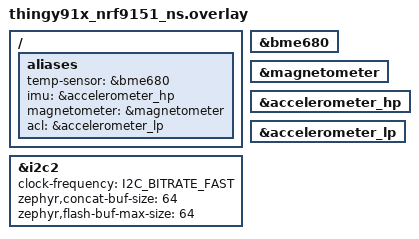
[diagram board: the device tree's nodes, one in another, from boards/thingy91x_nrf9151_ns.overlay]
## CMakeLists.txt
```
cmake_minimum_required(VERSION 3.20.0)


find_package(Zephyr REQUIRED HINTS $ENV{ZEPHYR_BASE})
project(yes)

# NORDIC SDK APP START
target_sources(app PRIVATE src/encryption_helper.c)
target_sources(app PRIVATE src/mqtt_connection.c)
target_sources(app PRIVATE src/heartbeat.c)
target_sources(app PRIVATE src/shell_commands.c)
target_sources(app PRIVATE src/config.c)
target_sources(app PRIVATE src/main.c)
target_sources(app PRIVATE src/gnss.c)
target_sources(app PRIVATE src/lte_helper.c)
target_sources(app PRIVATE src/fota.c)
target_sources(app PRIVATE drivers/led/led_driver.c)
target_sources(app PRIVATE src/pem_command.c)
target_sources(app PRIVATE src/sensor.c)
target_sources(app PRIVATE src/modem_info.c)
# NORDIC SDK APP END
```

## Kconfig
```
#  Kestrel Device Configuration

menu "Tracker Demo"
config TRACKER_VERSION_MAJOR
	int "Major verison number"
	default 0

config TRACKER_VERSION_MINOR
	int "Minor verison number"
	default 2

config TRACKER_VERSION_PATCH
	int "Patch verison number"
	default 0

config MQTT_CLIENT_ID
	string "Device ID"
	help
	  Use a custom Device ID string. If not set, the ID will be
	  generated based on IMEI number (for nRF91 Series based targets) or
	  randomly (for other platforms).
	default "359404230244148"

config MQTT_SUB_TOPIC
	string "MQTT subscribe topic"
	default "/input"

config MQTT_BROKER_HOSTNAME
	string "MQTT broker hostname"
	default "18.234.99.151"

config MQTT_BROKER_PORT
	int "MQTT broker port"
	default 8883

config MQTT_MESSAGE_BUFFER_SIZE
	int "MQTT message buffer size"
	default 128

config MQTT_PAYLOAD_BUFFER_SIZE
	int "MQTT payload buffer size"
	default 256

config MQTT_PUBLISH_INTERVAL
	int "Fix interval (sec) for publishing the GPS fixes"
	range 1 600
	default 1
	help
	  Fix interval (in seconds) for publishing GPS fixes.
      
config MQTT_RECONNECT_DELAY_S
	int "Seconds to delay before attempting to reconnect to the broker."
	default 60

config BUTTON_EVENT_PUBLISH_MSG
	string "The message to publish on a button event"
	default "Test Message"

config TLS
	bool "Enable TLS"
	default y
endmenu

menu "Zephyr Kernel"
source "Kconfig.zephyr"
endmenu
```

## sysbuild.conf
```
SB_CONFIG_BOOTLOADER_MCUBOOT=y


SB_CONFIG_BOOT_SIGNATURE_KEY_FILE="C:/Nordic/myApps/key_file/mcu_sign.pem"
SB_CONFIG_BOOT_SIGNATURE_TYPE_ECDSA_P256=y
#SB_CONFIG_SECURE_BOOT_SIGNING_KEY_FILE="C:/Nordic/myApps/key_file/mcu_sign.pem"
#SB_CONFIG_SECURE_BOOT_SIGNATURE_TYPE_ECDSA=y
```

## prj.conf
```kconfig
# System
CONFIG_REBOOT=y

# Logging
CONFIG_LOG=y
CONFIG_LOG_PRINTK=y
CONFIG_LOG_CMDS=y
CONFIG_LOG_DEFAULT_LEVEL=3
# Enable log colors
CONFIG_LOG_BACKEND_SHOW_COLOR=y


CONFIG_SERIAL=y
CONFIG_GPIO=y
CONFIG_I2C_GPIO=y

# Peripherals
CONFIG_DK_LIBRARY=y
CONFIG_I2C=y


# Newlib
CONFIG_NEWLIB_LIBC=y
CONFIG_FPU=y
CONFIG_NEWLIB_LIBC_FLOAT_PRINTF=y

# Networking
CONFIG_NETWORKING=y
CONFIG_NET_NATIVE=n
CONFIG_NET_SOCKETS_OFFLOAD=y
CONFIG_NET_SOCKETS=y
CONFIG_POSIX_API=y

# Memory
CONFIG_THREAD_ANALYZER=y


# Modem library
CONFIG_NRF_MODEM_LIB=y
CONFIG_MODEM_KEY_MGMT=y
CONFIG_MODEM_INFO=y
CONFIG_MODEM_INFO_ADD_NETWORK=y
CONFIG_MODEM_INFO_ADD_SIM=y
CONFIG_MODEM_INFO_ADD_SIM_IMSI=y
CONFIG_MODEM_INFO_ADD_SIM_ICCID=y
CONFIG_MODEM_INFO_ADD_DEVICE=y
CONFIG_MODEM_INFO_ADD_DATE_TIME=n


# LTE link control
CONFIG_LTE_LINK_CONTROL=y
CONFIG_LTE_NETWORK_MODE_LTE_M_NBIOT_GPS=y
CONFIG_LTE_LC_EDRX_MODULE=n
CONFIG_LTE_LC_PSM_MODULE=y

# AT commands interface
CONFIG_AT_HOST_LIBRARY=n
CONFIG_UART_INTERRUPT_DRIVEN=y

# MQTT
# Enable and configure the MQTT library
CONFIG_MQTT_LIB=y
CONFIG_MQTT_CLEAN_SESSION=y

# Core settings API
CONFIG_SETTINGS=y

# Store in a flash circular buffer
CONFIG_FCB=y
CONFIG_SETTINGS_FCB=y
CONFIG_SETTINGS=y

# Flash and mapping
CONFIG_FLASH=y
CONFIG_FLASH_MAP=y

# Shell & logging on your existing console

CONFIG_DK_LIBRARY=y
CONFIG_GPIO=y
CONFIG_SENSOR=y
CONFIG_NRF_MODEM_LIB=y

CONFIG_NET_PKT_RX_COUNT=4
CONFIG_NET_BUF_RX_COUNT=8
CONFIG_NET_BUF_DATA_SIZE=256

CONFIG_MAIN_STACK_SIZE=10000
#CONFIG_LOG_BUFFER_SIZE=6000
CONFIG_HEAP_MEM_POOL_SIZE=40000  
CONFIG_SHELL_STACK_SIZE=6096
CONFIG_SYSTEM_WORKQUEUE_STACK_SIZE=8096
CONFIG_MBEDTLS_HEAP_SIZE=1500

#TLS
CONFIG_NETWORKING=y
CONFIG_NET_NATIVE=n
CONFIG_NET_SOCKETS_OFFLOAD=y
# Enable TLS support in Zephyr sockets
CONFIG_NET_SOCKETS=y
CONFIG_MQTT_LIB_TLS=y
# Enable MbedTLS for TLS
CONFIG_MBEDTLS=y
CONFIG_MBEDTLS_ENABLE_HEAP=y
# Enable modem TLS credential storage
CONFIG_MODEM_KEY_MGMT=y

#crypto
# Enable PSA Crypto core
CONFIG_NRF_SECURITY=y
CONFIG_BUILD_WITH_TFM=y
CONFIG_MBEDTLS_PSA_CRYPTO_C=y
CONFIG_PSA_WANT_GENERATE_RANDOM=y
CONFIG_PSA_WANT_KEY_TYPE_AES=y
CONFIG_PSA_WANT_ALG_GCM=y
CONFIG_TFM_PROFILE_TYPE_NOT_SET=y
CONFIG_PSA_CRYPTO_DRIVER_CC3XX=y
CONFIG_PM_PARTITION_SIZE_TFM_SRAM=0x10000
CONFIG_BOOTLOADER_MCUBOOT=y
CONFIG_MBEDTLS_PSA_CRYPTO_STORAGE_C=y
CONFIG_TFM_ITS_ENCRYPTED=y
CONFIG_PSA_WANT_ALG_PBKDF2_HMAC=y
CONFIG_PSA_WANT_ALG_SHA3_256=y
CONFIG_PSA_WANT_KEY_TYPE_PASSWORD=y
CONFIG_PSA_WANT_ALG_HMAC=y

# Image manager
CONFIG_IMG_MANAGER=y
CONFIG_FLASH=y
CONFIG_FLASH_MAP=y
CONFIG_STREAM_FLASH=y
CONFIG_IMG_ERASE_PROGRESSIVELY=y
CONFIG_DOWNLOADER=y
CONFIG_DOWNLOADER_STACK_SIZE=4096
CONFIG_DFU_TARGET=y
CONFIG_MODEM_KEY_MGMT=y
CONFIG_FOTA_DOWNLOAD=y

CONFIG_SHELL_STACK_SIZE=6096
CONFIG_SHELL=y
CONFIG_SHELL_CMDS=y
CONFIG_SHELL_DEVICE_HELPERS=n
CONFIG_SHELL=y
CONFIG_SHELL_BACKEND_SERIAL=y   # use the existing console UART/USB-CDC
CONFIG_SHELL_LOG_BACKEND=y      # pipe LOG_* into the shell prompt
CONFIG_UART_INTERRUPT_DRIVEN=y  # required by the shell’s serial backend
CONFIG_SHELL_PROMPT_UART="x"
CONFIG_NEWLIB_LIBC=y
CONFIG_DATE_SHELL=n
CONFIG_DEVICE_SHELL=y
CONFIG_DEVMEM_SHELL=y
CONFIG_KERNEL_SHELL=y
CONFIG_I2C_SHELL=y
CONFIG_SHELL_BACKEND_SERIAL_RX_RING_BUFFER_SIZE=528
CONFIG_SPI=y
CONFIG_SPI_SHELL=y
CONFIG_SENSOR_SHELL=y
CONFIG_AT_SHELL=y

CONFIG_NET_BUF=y
CONFIG_ZCBOR=y
CONFIG_CRC=y
CONFIG_MCUMGR=y
CONFIG_STREAM_FLASH=y
CONFIG_FLASH_MAP=y
CONFIG_THREAD_MONITOR=y
CONFIG_MCUMGR_GRP_OS_TASKSTAT=y
CONFIG_STATS=y
CONFIG_STATS_NAMES=y
CONFIG_FLASH=y
CONFIG_IMG_MANAGER=y
CONFIG_MCUMGR_GRP_IMG=y
CONFIG_MCUMGR_GRP_OS=y
CONFIG_MCUMGR_GRP_STAT=y
CONFIG_MCUBOOT_UTIL_LOG_LEVEL_WRN=y
CONFIG_MCUMGR_GRP_OS_ECHO=y
CONFIG_BASE64=y
CONFIG_CRC=y
CONFIG_MCUMGR_TRANSPORT_UART=y
CONFIG_CONSOLE=y
CONFIG_UART_INTERRUPT_DRIVEN=y
# CONFIG_UART_CONSOLE=n
# CONFIG_SHELL=y
# CONFIG_SHELL_BACKEND_DUMMY=y
# CONFIG_MCUMGR_TRANSPORT_DUMMY=y
# CONFIG_MCUMGR_TRANSPORT_SHELL=y
# CONFIG_SHELL_LOG_BACKEND=n
# CONFIG_SHELL_BACKEND_SERIAL=n

# CONFIG_MCUMGR_LOG_LEVEL_DBG=y
# CONFIG_DOWNLOADER_LOG_LEVEL_DBG=y
# CONFIG_FOTA_DOWNLOAD_LOG_LEVEL_DBG=y
# CONFIG_LTE_LINK_CONTROL_LOG_LEVEL_DBG=y


CONFIG_SENSOR=y
CONFIG_BMP388=y
CONFIG_IIS2MDC=y
CONFIG_ICM42688=y
CONFIG_WATCHDOG=y
```

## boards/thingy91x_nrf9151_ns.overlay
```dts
&i2c2 {
	status = "okay";
	clock-frequency = <I2C_BITRATE_FAST>;
    zephyr,concat-buf-size = <64>;
    zephyr,flash-buf-max-size = <64>;
};

&bme680 {
	status = "okay";
};

&magnetometer {
    status = "okay";
};

&accelerometer_hp {
    status = "okay";
};

&accelerometer_lp {
    status = "okay";
};

/ {

	aliases {
		temp-sensor = &bme680;
		imu = &accelerometer_hp;
		magnetometer = &magnetometer;
		acl = &accelerometer_lp;
	};
};
```

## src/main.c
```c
#include <stdio.h>
#include <string.h>
#include <stdlib.h>
#include <zephyr/device.h>
#include <zephyr/drivers/gpio.h>
#include <zephyr/devicetree.h>
#include <zephyr/kernel.h>
#include <zephyr/sys/reboot.h>
#include <zephyr/net/socket.h>
#include <zephyr/net/mqtt.h>
#include <modem/nrf_modem_lib.h>
#include <modem/lte_lc.h>
#include <modem/modem_info.h>
#include <dk_buttons_and_leds.h>
#include <nrf_modem_gnss.h>
#include <nrf_modem_at.h>
#include <zephyr/sys/heap_listener.h>
#include "mqtt_connection.h"
#include "gnss.h"
#include "nrf.h"
#include "heartbeat.h"
#include "lte_helper.h"
#include "shell_commands.h"
#include "modem_info.h"
#include "fota.h"
#include "config.h"
#include "encryption_helper.h"
#include "sensor.h"
#include "../drivers/led/led_driver.h"
#include <zephyr/drivers/watchdog.h>
LOG_MODULE_REGISTER(loop, LOG_LEVEL_INF);

//Watchdog timer setup for main
#define WDT_TIMEOUT_MS 120000
static const struct device *wdt;
static int wdt_chan_id;


/* Initialize the watchdog */
int wdt_init(void)
{
    wdt = DEVICE_DT_GET(DT_NODELABEL(wdt0));
    if (!device_is_ready(wdt)) {
        LOG_ERR("WDT device not ready");
        return -ENODEV;
    }

    struct wdt_timeout_cfg wdt_cfg = {
    .window.min = 0,
    .window.max = 16384,    
    .flags = WDT_FLAG_RESET_SOC
    };

    wdt_chan_id = wdt_install_timeout(wdt, &wdt_cfg);
    if (wdt_chan_id < 0) {
        LOG_ERR("Failed to install WDT timeout, err: %d", wdt_chan_id);
        return wdt_chan_id;
    }

    int err = wdt_setup(wdt, WDT_OPT_PAUSE_HALTED_BY_DBG);
    if (err < 0) {
        LOG_ERR("Failed to setup WDT, err: %d", err);
        return err;
    }

    LOG_INF("Watchdog initialized with %d ms timeout", WDT_TIMEOUT_MS);
    return 0;
}




/**
 * @brief Initialize all system components
 */
static int init(void)
{
    int err = 0;
    
    LOG_INF("NEW APP STARTING");
    
    

    err = open_persistent_key();
    if (err) {
        LOG_ERR("open_persistent_key: %d", err);
    } else {
        LOG_INF("Persistent key opened successfully");
    }

    const struct device *i2c = DEVICE_DT_GET(DT_NODELABEL(i2c_bb0));
    if (device_is_ready(i2c) && ktd2026_init(&g_ktd, i2c, 0x30) == 0 && ktd2026_init(&k_ktd, i2c, 0x31) == 0) {
        LOG_INF("KTD2026 initialized successfully");
        ktd2026_blink_white_1hz_30();
        ktd2026_blink_white_1hz_31();
    } 
    else {
        LOG_ERR("Failed to initialize KTD2026 LED driver");
        return -ENODEV;
    }


    sensor_init();
    k_sleep(K_MSEC(30000)); // Wait for sensor initialization
    parse_encrypted_blob(); 
    config_init();
    gnss_int();
    err = modem_configure();
    if (err) {
        LOG_ERR("modem_configure failed: %d", err);
        return err;
    }
    lte_data_start();
    mqtt_init();

    return 0;
}

/**
 * @brief Main application entry point
 */
int main(void)
{
    int err, start, end;
    k_sleep(K_MSEC(2000));
    if (boot_write_img_confirmed() != 0) {
        printk("Failed to confirm firmware!\n");
    } else {
        printk("Firmware confirmed!\n");
    }


    

    err = init();
    if (err) {
        LOG_ERR("Initialization failed: %d", err);
    } else {
        LOG_INF("INIT GOOD");
    }
    
    if (wdt_init() != 0) {
        LOG_ERR("Watchdog initialization failed!");
    }

    while (1) {
        start = k_uptime_get();
        gnss_main_loop();
        wdt_feed(wdt, wdt_chan_id);
        end = k_uptime_get();
    }
    
    return 0;
}
```

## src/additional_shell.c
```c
/* Revised KTD2026EWE-TR Zephyr Shell Driver */
#include <zephyr/kernel.h>
#include <zephyr/shell/shell.h>
#include <zephyr/drivers/i2c.h>
#include <zephyr/device.h>
#include <zephyr/logging/log.h>
#include <stdlib.h>
#include <errno.h>
#include <string.h>

LOG_MODULE_REGISTER(led_shell, LOG_LEVEL_INF);

#define KTD2026_I2C_ADDR 0x30
static const struct device *i2c_dev = DEVICE_DT_GET(DT_NODELABEL(i2c1));

#define KTD2026_EN_RST          0x00
#define KTD2026_FLASH_PERIOD    0x01
#define KTD2026_FLASH_DUTY      0x02
#define KTD2026_LED_EN          0x03
#define KTD2026_TRISE_TFALL     0x04
#define KTD2026_LED1            0x05
#define KTD2026_LED2            0x06
#define KTD2026_LED3            0x07
#define KTD2026_TIMER_CTRL      0x08

#define KTD2026_LED_CURRENT_MAX 0xBF
#define KTD2026_FLASH_PERIOD_MAX 0x1F
#define KTD2026_FLASH_DUTY_MAX   0x07

static uint8_t led_en_state = 0;

static int ktd2026_write_reg(uint8_t reg, uint8_t value)
{
    uint8_t buf[2] = {reg, value};
    for (int i = 0; i < 3; i++) {
        int ret = i2c_write(i2c_dev, buf, sizeof(buf), KTD2026_I2C_ADDR);
        if (ret == 0) {
            LOG_DBG("Wrote reg 0x%02X = 0x%02X, ret=%d", reg, value, ret);
            return 0;
        }
        k_sleep(K_MSEC(5));
    }

    LOG_DBG("Wrote reg 0x%02X = 0x%02X, ret=%d", reg, value, ret);
    return -EIO;
}

static int ktd2026_read_reg(uint8_t reg, uint8_t *value)
{
    return i2c_write_read(i2c_dev, KTD2026_I2C_ADDR, &reg, 1, value, 1);
}

static int ktd2026_set_led_current(uint8_t led, uint8_t current)
{
    if (current > KTD2026_LED_CURRENT_MAX) current = KTD2026_LED_CURRENT_MAX;
    uint8_t reg = (led == 1) ? KTD2026_LED1 : (led == 2) ? KTD2026_LED2 : (led == 3) ? KTD2026_LED3 : 0xFF;
    if (reg == 0xFF) return -EINVAL;
    return ktd2026_write_reg(reg, current);
}

static int ktd2026_set_led_enable(uint8_t led, bool enable)
{
    if (led < 1 || led > 3) return -EINVAL;
    uint8_t bit = BIT(led - 1);
    led_en_state = enable ? (led_en_state | bit) : (led_en_state & ~bit);
    return ktd2026_write_reg(KTD2026_LED_EN, led_en_state);
}

static int ktd2026_set_flash_period(uint8_t period)
{
    if (period > KTD2026_FLASH_PERIOD_MAX) period = KTD2026_FLASH_PERIOD_MAX;
    return ktd2026_write_reg(KTD2026_FLASH_PERIOD, period);
}

static int ktd2026_set_flash_duty(uint8_t duty)
{
    if (duty > KTD2026_FLASH_DUTY_MAX) duty = KTD2026_FLASH_DUTY_MAX;
    return ktd2026_write_reg(KTD2026_FLASH_DUTY, duty);
}

static int ktd2026_set_timer_control(uint8_t timer_sel, bool enable)
{
    uint8_t value;
    if (ktd2026_read_reg(KTD2026_TIMER_CTRL, &value) < 0) return -EIO;
    value &= ~0x06;
    value |= (timer_sel << 1) & 0x06;
    value = enable ? (value | 0x01) : (value & ~0x01);
    return ktd2026_write_reg(KTD2026_TIMER_CTRL, value);
}

static int ktd2026_init(void)
{
    if (!device_is_ready(i2c_dev)) {
        LOG_ERR("I2C device not ready");
        return -ENODEV;
    }
    k_sleep(K_MSEC(1));
    if (ktd2026_write_reg(KTD2026_EN_RST, 0x00) < 0) return -EIO;
    k_sleep(K_MSEC(10));
    if (ktd2026_write_reg(KTD2026_LED_EN, 0x00) < 0) return -EIO;
    for (int i = 1; i <= 3; i++) {
        if (ktd2026_set_led_current(i, 0) < 0) return -EIO;
    }
    if (ktd2026_write_reg(KTD2026_TIMER_CTRL, 0x00) < 0) return -EIO;
    return 0;
}

/* Shell Commands */
static int cmd_led_init(const struct shell *shell, size_t argc, char *argv[]) {
    int ret = ktd2026_init();
    shell_print(shell, ret == 0 ? "LED controller initialized" : "Init failed: %d", ret);
    return ret;
}

static int cmd_led_on(const struct shell *shell, size_t argc, char *argv[]) {
    if (argc != 2) return -EINVAL;
    int led = atoi(argv[1]);
    return ktd2026_set_led_enable(led, true);
}

static int cmd_led_off(const struct shell *shell, size_t argc, char *argv[]) {
    if (argc != 2) return -EINVAL;
    int led = atoi(argv[1]);
    return ktd2026_set_led_enable(led, false);
}

static int cmd_led_set(const struct shell *shell, size_t argc, char *argv[]) {
    if (argc != 3) return -EINVAL;
    int led = atoi(argv[1]);
    int current = atoi(argv[2]);
    return ktd2026_set_led_current(led, current);
}

SHELL_STATIC_SUBCMD_SET_CREATE(led_subcmds,
    SHELL_CMD(init, NULL, "Initialize LED controller", cmd_led_init),
    SHELL_CMD(on, NULL, "Turn LED on", cmd_led_on),
    SHELL_CMD(off, NULL, "Turn LED off", cmd_led_off),
    SHELL_CMD(set, NULL, "Set LED current", cmd_led_set),
    SHELL_SUBCMD_SET_END
);

SHELL_CMD_REGISTER(led, &led_subcmds, "KTD2026 LED driver commands", NULL);


static int cmd_dfu_reboot(const struct shell *shell, size_t argc, char **argv)
{
    ARG_UNUSED(argc);
    ARG_UNUSED(argv);

    int err = boot_write_img_confirmed();
    if (err != 0) {
        shell_error(shell, "Failed to confirm image: %d", err);
        return err;
    }

    err = boot_set_pending(false);  // false = permanent
    if (err != 0) {
        shell_error(shell, "Failed to set boot pending: %d", err);
        return err;
    }

    shell_print(shell, "Rebooting into MCUboot for DFU...");
    k_sleep(K_MSEC(100)); // allow shell print to flush

    sys_reboot(SYS_REBOOT_COLD);
    return 0; // won't be reached
}

SHELL_CMD_REGISTER(dfu_reboot, NULL, "Reboot into MCUboot DFU mode", cmd_dfu_reboot);
```

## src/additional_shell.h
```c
#ifndef ADDITIONAL_SHELL_H
#define ADDITIONAL_SHELL_H

#include <zephyr/shell/shell.h>

/* LED shell command declarations */
extern const struct shell *led_shell;

#endif /* ADDITIONAL_SHELL_H */ 
```

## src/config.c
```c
#include "config.h"
#include <stdio.h>
#include <string.h>
#include <stdlib.h>
#include <zephyr/logging/log.h>
#include <zephyr/logging/log.h>
#include <zephyr/kernel.h>
#include <zephyr/sys/reboot.h>
#include <zephyr/net/socket.h>
#include <zephyr/net/mqtt.h>
#include <zephyr/net/tls_credentials.h>
#include <zephyr/random/random.h>
#include <nrf_modem_at.h>
#include <modem/modem_key_mgmt.h>
#include <zephyr/sys/crc.h>
#include <zephyr/storage/flash_map.h>
#include "encryption_helper.h"

LOG_MODULE_REGISTER(configuration, LOG_LEVEL_INF);
char json_payload[JSON_BUF_SIZE] = "NO PVT";
char sensor_payload[JSON_BUF_SIZE] = "NO SENSOR DATA";
char json_payload_lte[JSON_BUF_SIZE] = "NO LTE";
char json_bmp390[JSON_BUF_SIZE] = "NO BMP390 DATA";
char json_iis2mdc[JSON_BUF_SIZE] = "NO IIS2MDC DATA";
char json_icm42688[JSON_BUF_SIZE] = "NO ICM42688 DATA";
char topic_gps[DEFAULT_LEN] = "/gps";
char topic_sensor[DEFAULT_LEN] = "/sensor";
char topic_lte[DEFAULT_LEN] = "/lte";
char pwd[64] = "Kalscott123";
char usr[64] = "admin";
char firmware_filename[FOTA_FILE_NAME_MAX_LEN] = "firmware.bin";
struct mqtt_utf8 struct_pass;
struct mqtt_utf8 struct_user;
system_enable_t sys_enable_config;
enum fota_state current_state = FOTA_IDLE;
mqtt_config_t mqtt_config;
ota_config_t ota_config;
hardware_info_t hw_info;
modem_info_t modem_info;
sensor_config_t sensor_config;
gnss_config_t gnss_config;
customer_info_t customer_info;
message_settings_t msg_settings;


ConfigEntry entries[MAX_ENTRIES];
int num_entries = 0;

void set_filename(void) {
    const char root[] = "firmware_storage";
    const char file[] = "zephyr_signed.bin";

    char customer[MQTT_MAX_STR_LEN];
    char device[MQTT_MAX_STR_LEN];


    // copy results immediately so we don't lose them
    const char *cfg_val = get_config("name");
    if (cfg_val) {
        strncpy(customer, cfg_val, sizeof(customer));
        customer[sizeof(customer) - 1] = '\0'; // ensure null-terminated
    } else {
        customer[0] = '\0';
    }

    cfg_val = get_config("mq_clid");
    if (cfg_val) {
        strncpy(device, cfg_val, sizeof(device));
        device[sizeof(device) - 1] = '\0';
    } else {
        device[0] = '\0';
    }

    // build path
    snprintf(firmware_filename, sizeof(firmware_filename),
             "%s/%s/%s/%s", root, customer, device, file);

    printf("Firmware filename: %s\n", firmware_filename);
}


int update_crc(void)
{
    const struct flash_area *fa;
    int err = flash_area_open(FLASH_AREA_ID(encrypted_blob_slot0), &fa);
    if (err) {
        LOG_ERR("flash_area_open for CRC failed: %d", err);
        return err;
    }

    uint32_t new_crc = manual_crc32(ENCRYPTED_BLOB_ADDR, ENCRYPTED_BLOB_SIZE - 4);
    uint32_t crc_offset = CRC_LOCATION_OFFSET;
    uint32_t page_start = (crc_offset / FLASH_PAGE_SIZE) * FLASH_PAGE_SIZE;

    static uint8_t page_buf[FLASH_PAGE_SIZE];

    err = flash_area_read(fa, page_start, page_buf, FLASH_PAGE_SIZE);
    if (err) {
        LOG_ERR("flash_area_read for CRC page failed: %d", err);
        flash_area_close(fa);
        return err;
    }

    uint32_t crc_offset_in_page = crc_offset - page_start;
    memcpy(&page_buf[crc_offset_in_page], &new_crc, 4);

    err = flash_area_erase(fa, page_start, FLASH_PAGE_SIZE);
    if (err) {
        LOG_ERR("flash_area_erase CRC page failed: %d", err);
        flash_area_close(fa);
        return err;
    }

    err = flash_area_write(fa, page_start, page_buf, FLASH_PAGE_SIZE);
    if (err) {
        LOG_ERR("CRC write failed: %d", err);
    } else {
        LOG_INF("CRC updated: 0x%08X at offset 0x%x", new_crc, crc_offset);
    }

    flash_area_close(fa);
    return err;
}

uint32_t manual_crc32(const uint8_t *data, size_t len) {
    uint32_t crc = 0xFFFFFFFF;

    LOG_INF("Starting manual CRC-32 over %u bytes", (unsigned int)len);

    for (size_t i = 0; i < len; i++) {
        uint8_t byte = data[i];
        crc ^= byte;
        for (int j = 0; j < 8; j++) {
            if (crc & 1)
                crc = (crc >> 1) ^ 0xEDB88320;
            else
                crc >>= 1;
        }
    }

    crc ^= 0xFFFFFFFF;

    LOG_INF("Final manual CRC-32: 0x%08X", crc);
    return crc;
}

const char *get_config(const char *aad)
{
    static char decrypted[DECRYPTED_OUTPUT_MAX]; // persistent output
    size_t decrypted_len = 0;

    for (int i = 0; i < num_entries; i++) {
        ConfigEntry *e = &entries[i];

        if (e->aad_len == strlen(aad) &&
            memcmp(e->aad, aad, e->aad_len) == 0) {

            int ret = decrypt_config_field_data(
                (const char *)e->ciphertext, e->ciphertext_len,
                (const char *)e->iv,
                (const char *)e->aad, e->aad_len,
                decrypted, &decrypted_len
            );

            if (ret != 0) {
                LOG_ERR("Decryption failed for AAD: %s", aad);
                return NULL;
            }

            decrypted[decrypted_len] = '\0'; // null-terminate
            return decrypted;
        }
    }

    LOG_WRN("AAD not found: %s", aad);
    return "NULL";
}

void parse_encrypted_blob(void)
{
    const uint8_t *start = ENCRYPTED_BLOB_ADDR;
    const uint8_t *end = ENCRYPTED_BLOB_ADDR + ENCRYPTED_BLOB_SIZE;
    const size_t entry_span = ENTRY_SIZE;
    const size_t max_offset = CRC_LOCATION_OFFSET;

    LOG_INF("Begin blob parsing at address %p, total size: %d", (void *)start, ENCRYPTED_BLOB_SIZE);

    uint32_t computed_crc = manual_crc32(start, ENCRYPTED_BLOB_SIZE - 4);
    uint32_t stored_crc = *(uint32_t *)(start + CRC_LOCATION_OFFSET);
    if (computed_crc != stored_crc) {
        LOG_WRN("CRC mismatch: computed=0x%08X, stored=0x%08X", computed_crc, stored_crc);
    } else {
        LOG_INF("CRC check passed: 0x%08X", computed_crc);
    }

    num_entries = 0;

    for (uintptr_t offset = 0; offset + entry_span <= max_offset && num_entries < MAX_ENTRIES; offset += entry_span) {
        const uint8_t *ptr = start + offset;

        if (ptr[0] == 0xFF) {
            continue;
        }

        ConfigEntry *e = &entries[num_entries];
        e->mem_offset = offset;

        e->iv_len = *ptr++;
        if (e->iv_len > MAX_IV_LEN || ptr + e->iv_len > end) {
            LOG_ERR("Invalid or oversized IV length: %d at entry %d", e->iv_len, num_entries);
            continue;
        }
        memcpy(e->iv, ptr, e->iv_len);
        ptr += e->iv_len;

        if (ptr + 2 > end) continue;
        e->aad_len = ptr[0] | (ptr[1] << 8);
        ptr += 2;
        if (e->aad_len > MAX_AAD_LEN || ptr + e->aad_len > end) {
            LOG_ERR("Invalid or oversized AAD length: %d at entry %d", e->aad_len, num_entries);
            continue;
        }
        memcpy(e->aad, ptr, e->aad_len);
        ptr += e->aad_len;

        if (ptr + 2 > end) continue;
        e->ciphertext_len = ptr[0] | (ptr[1] << 8);
        ptr += 2;
        if (e->ciphertext_len > MAX_CIPHERTEXT_LEN || ptr + e->ciphertext_len > end) {
            LOG_ERR("Invalid or oversized ciphertext length: %d at entry %d", e->ciphertext_len, num_entries);
            continue;
        }
        memcpy(e->ciphertext, ptr, e->ciphertext_len);
        ptr += e->ciphertext_len;

        LOG_INF("Parsed entry %d @ offset 0x%04X: IV=%d, AAD=%d, Cipher+Tag=%d",
                num_entries, (int)offset, e->iv_len, e->aad_len, e->ciphertext_len);

        num_entries++;
    }

    LOG_INF("Total parsed entries: %d", num_entries);
}

void parse_hardware_info(hardware_info_t *cfg) {
    const char *val;

    if (!cfg) {
    LOG_ERR("parse_hardware_info: cfg is NULL!");
    return;
    }
    cfg->sn[0] = cfg->hw_ver[0] = cfg->fw_ver[0] = '\0';
    cfg->power_enabled = false;


    val = get_config("hw_info");
    if (val) {

        sscanf(val, "%31[^,],%15[^,],%15[^,]",
               cfg->sn, cfg->hw_ver, cfg->fw_ver);
    }

    val = get_config("pwr_st");
    if (val) {
        cfg->power_enabled = atoi(val) ? true : false;
    }
}

void parse_modem_info(modem_info_t *cfg) {
    const char *val;

    val = get_config("mdm_info");
    if (val) {
        sscanf(val, "%31[^,],%31[^,],%20[^,]", 
               cfg->make, cfg->model, cfg->fw_ver);
    }

    val = get_config("mdm_imei");
    if (val) strncpy(cfg->imei, val, sizeof(cfg->imei) - 1);

    val = get_config("sim_info"); 
    if (val) {
        sscanf(val, "%31[^,],%31[^,]", cfg->sim, cfg->esim);
    }

    val = get_config("lte_bnd");
    if (val) {
        cfg->lte_bandmask = (uint16_t)strtol(val, NULL, 0);
    }
}

void parse_system_enable_config(void) {
    memset(&sys_enable_config, 0, sizeof(sys_enable_config));

    const char *raw = get_config("sys_en");
    if (!raw) {
        return;
    }

    uint16_t bitmask = (uint16_t)strtol(raw, NULL, 0);

    sys_enable_config.lte_en        = bitmask & SYS_EN_LTE_EN;
    sys_enable_config.irid_en       = bitmask & SYS_EN_IRID_EN;
    sys_enable_config.psm_en        = bitmask & SYS_EN_PSM_EN;
    sys_enable_config.hw_en         = bitmask & SYS_EN_HW_EN;
    sys_enable_config.mdm_en        = bitmask & SYS_EN_MDM_EN;
    sys_enable_config.gnss_en       = bitmask & SYS_EN_GNSS_EN;
    sys_enable_config.imu_en        = bitmask & SYS_EN_IMU_EN;
    sys_enable_config.comp_en       = bitmask & SYS_EN_COMP_EN;
    sys_enable_config.baro_en       = bitmask & SYS_EN_BARO_EN;
    sys_enable_config.mqtt_en       = bitmask & SYS_EN_MQTT_EN;
    sys_enable_config.ota_en        = bitmask & SYS_EN_OTA_EN;
    sys_enable_config.debug_mode    = bitmask & SYS_EN_DEBUG_MODE;
    sys_enable_config.factory_mode  = bitmask & SYS_EN_FACTORY_MODE;
}

void parse_mqtt_config(mqtt_config_t *cfg) {
    const char *val;
    val = get_config("mq_rt");
    if (val) cfg->publish_rate = atoi(val);
    val = get_config("mq_addr");
    if (val) strncpy(cfg->broker_addr, val, sizeof(cfg->broker_addr) - 1);
    val = get_config("mq_port");
    if (val) cfg->broker_port = atoi(val);
    val = get_config("mq_clid");
    if (val) strncpy(cfg->client_id, val, sizeof(cfg->client_id) - 1);
    val = get_config("mq_user");
    if (val) strncpy(cfg->username, val, sizeof(cfg->username) - 1);
    val = get_config("mq_pass");
    if (val) strncpy(cfg->password, val, sizeof(cfg->password) - 1);
    val = get_config("mq_tls");
    if (val) cfg->tls_enabled = atoi(val) ? true : false;
    val = get_config("mq_qos");
    if (val) cfg->qos = atoi(val);
}

void parse_ota_config(ota_config_t *cfg) {
    const char *val;
    val = get_config("ota_int");
    if (val) cfg->check_interval = atoi(val);
    val = get_config("ota_addr");
    if (val) strncpy(cfg->server_addr, val, sizeof(cfg->server_addr) - 1);
    val = get_config("ota_port");
    if (val) cfg->server_port = atoi(val);
    val = get_config("ota_user");
    if (val) strncpy(cfg->username, val, sizeof(cfg->username) - 1);
    val = get_config("ota_pass");
    if (val) strncpy(cfg->password, val, sizeof(cfg->password) - 1);
    val = get_config("ota_tls");
    if (val) cfg->tls_enabled = atoi(val) ? true : false;
    val = get_config("ota_cert");
    if (val) strncpy(cfg->cert_tag, val, sizeof(cfg->cert_tag) - 1);
}

void parse_sensor_config(sensor_config_t *cfg) {
    const char *val;

    val = get_config("sens_rt");
    if (val) cfg->sampling_rate = atoi(val);
    else cfg->sampling_rate = 10;

    val = get_config("sens_flt");
    if (val) cfg->filter_window = atoi(val);
    else cfg->filter_window = 5;

    val = get_config("sens_cal");
    if (val) cfg->auto_calibrate = atoi(val) ? true : false;
    else cfg->auto_calibrate = false;
}

void parse_gnss_config(gnss_config_t *cfg) {
    const char *val;

    val = get_config("gnss_rt");
    if (val) cfg->update_rate = atoi(val);
    else cfg->update_rate = 1;

    val = get_config("gnss_ver");
    if (val) strncpy(cfg->version, val, sizeof(cfg->version) - 1);
    else strncpy(cfg->version, "u-blox8", sizeof(cfg->version));

    val = get_config("gnss_con");
    if (val) cfg->constellation_mask = (uint8_t)strtol(val, NULL, 0);
    else cfg->constellation_mask = 0x01;

    val = get_config("gnss_acc");
    if (val) cfg->accuracy_threshold = atoi(val);
    else cfg->accuracy_threshold = 3;
}

void parse_customer_info(customer_info_t *cfg) {
    const char *val;

    val = get_config("uas_num");
    if (val) strncpy(cfg->uas_num, val, sizeof(cfg->uas_num) - 1);

    val = get_config("cust_desc");
    if (val) strncpy(cfg->description, val, sizeof(cfg->description) - 1);

    val = get_config("uas_status");
    if (val) strncpy(cfg->uas_status, val, sizeof(cfg->uas_status) - 1);

    val = get_config("cust_f2");
    if (val) strncpy(cfg->field2, val, sizeof(cfg->field2) - 1);

    val = get_config("cust_f3");
    if (val) strncpy(cfg->field3, val, sizeof(cfg->field3) - 1);

    val = get_config("cust_f4");
    if (val) strncpy(cfg->field4, val, sizeof(cfg->field4) - 1);
}

void parse_message_settings(message_settings_t *cfg) {
    const char *v;

    // Defaults first (optional but recommended)
    strncpy(cfg->msg_format, "JSON", sizeof(cfg->msg_format)-1);
    strncpy(cfg->gps_format, "NMEA", sizeof(cfg->gps_format)-1);
    strncpy(cfg->units,      "METRIC", sizeof(cfg->units)-1);

    v = get_config("msg_fmt"); if (v) { cfg->msg_format[0] = '\0'; strncat(cfg->msg_format, v, sizeof(cfg->msg_format)-1); }
    v = get_config("gps_fmt"); if (v) { cfg->gps_format[0] = '\0'; strncat(cfg->gps_format, v, sizeof(cfg->gps_format)-1); }
    v = get_config("units");   if (v) { cfg->units[0]      = '\0'; strncat(cfg->units,      v, sizeof(cfg->units)-1); }
}








void print_hardware_info() {
    printf("=== Hardware Information ===\n");
    printf("Serial Number:        %s\n", hw_info.sn);
    printf("HW Version:           %s\n", hw_info.hw_ver);
    printf("FW Version:           %s\n", hw_info.fw_ver);
    printf("Power Status Enable:  %s\n", hw_info.power_enabled ? "Enabled" : "Disabled");
}

void print_modem_info() {
    printf("=== Modem Information ===\n");
    printf("Make:                 %s\n", modem_info.make);
    printf("Model:                %s\n", modem_info.model);
    printf("FW Version:           %s\n", modem_info.fw_ver);
    printf("IMEI:                 %s\n", modem_info.imei);
    printf("SIM Provider:         %s\n", modem_info.sim);
    printf("eSIM Provider:        %s\n", modem_info.esim);
    printf("LTE Bandmask:         0x%04X\n", modem_info.lte_bandmask);
}

void print_sensor_config() {
    printf("=== Sensor Configuration ===\n");
    printf("Sampling Rate (Hz):   %d\n", sensor_config.sampling_rate);
    printf("Filter Window Size:   %d\n", sensor_config.filter_window);
    printf("Auto Calibration:     %s\n", sensor_config.auto_calibrate ? "Enabled" : "Disabled");
}

void print_gnss_config() {
    printf("=== GNSS Configuration ===\n");
    printf("Update Rate (Hz):     %d\n", gnss_config.update_rate);
    printf("Module Version:       %s\n", gnss_config.version);
    printf("Constellation Mask:   0x%02X\n", gnss_config.constellation_mask);
    printf("Accuracy Threshold:   %d meters\n", gnss_config.accuracy_threshold);
}

void print_mqtt_config() {
    printf("=== MQTT Configuration ===\n");
    printf("Publish Rate:  %d\n", mqtt_config.publish_rate);
    printf("Broker Addr:   %s\n", mqtt_config.broker_addr);
    printf("Broker Port:   %d\n", mqtt_config.broker_port);
    printf("Client ID:     %s\n", mqtt_config.client_id);
    printf("Username:      %s\n", mqtt_config.username);
    printf("Password:      %s\n", mqtt_config.password);
    printf("TLS Enabled:   %s\n", mqtt_config.tls_enabled ? "Yes" : "No");
    printf("QoS:           %d\n", mqtt_config.qos);
}

void print_ota_config() {
    printf("=== OTA Configuration ===\n");
    printf("Check Interval: %d\n", ota_config.check_interval);
    printf("Server Addr:    %s\n", ota_config.server_addr);
    printf("Server Port:    %d\n", ota_config.server_port);
    printf("Username:       %s\n", ota_config.username);
    printf("Password:       %s\n", ota_config.password);
    printf("TLS Enabled:    %s\n", ota_config.tls_enabled ? "Yes" : "No");
    printf("Cert Tag:       %s\n", ota_config.cert_tag);
}

void print_customer_info() {
    printf("=== Customer Information ===\n");
    printf("UAS Number:           %s\n", customer_info.uas_num);
    printf("Description:          %s\n", customer_info.description);
    printf("UAS STATUS:           %s\n", customer_info.uas_status);
    printf("Custom Field 2:       %s\n", customer_info.field2);
    printf("Custom Field 3:       %s\n", customer_info.field3);
    printf("Custom Field 4:       %s\n", customer_info.field4);
}

void print_message_settings() {
    printf("=== Message Settings ===\n");
    printf("Message Format:       %s\n", msg_settings.msg_format);
    printf("GPS Format:           %s\n", msg_settings.gps_format);
    printf("Units:                %s\n", msg_settings.units);
}

void print_system_enable() {
    printf("=== System Enable Flags ===\n");
    printf("LTE Enabled:         %s\n", sys_enable_config.lte_en        ? "Yes" : "No");
    printf("Iridium Enabled:     %s\n", sys_enable_config.irid_en       ? "Yes" : "No");
    printf("Power Save Mode:     %s\n", sys_enable_config.psm_en        ? "Yes" : "No");
    printf("HW Info Reporting:   %s\n", sys_enable_config.hw_en         ? "Yes" : "No");
    printf("Modem Info:          %s\n", sys_enable_config.mdm_en        ? "Yes" : "No");
    printf("GNSS Enabled:        %s\n", sys_enable_config.gnss_en       ? "Yes" : "No");
    printf("IMU Enabled:         %s\n", sys_enable_config.imu_en        ? "Yes" : "No");
    printf("Compass Enabled:     %s\n", sys_enable_config.comp_en       ? "Yes" : "No");
    printf("Barometer Enabled:   %s\n", sys_enable_config.baro_en       ? "Yes" : "No");
    printf("MQTT Enabled:        %s\n", sys_enable_config.mqtt_en       ? "Yes" : "No");
    printf("OTA Enabled:         %s\n", sys_enable_config.ota_en        ? "Yes" : "No");
    printf("Debug Mode:          %s\n", sys_enable_config.debug_mode    ? "Yes" : "No");
    printf("Factory Mode:        %s\n", sys_enable_config.factory_mode  ? "Yes" : "No");
}
void print_all_configs() {
    print_hardware_info();
    print_modem_info();
    print_sensor_config();
    print_gnss_config();
    print_mqtt_config();
    print_ota_config();
    print_customer_info();
    print_message_settings();
}

void config_init() {
    parse_system_enable_config();
    if (sys_enable_config.debug_mode) {
        print_system_enable();
    }
    LOG_INF("System enable config parsed successfully.");

    if (sys_enable_config.hw_en) {
        memset(&hw_info, 0, sizeof(hw_info));
        parse_hardware_info(&hw_info);
    }
    LOG_INF("Hardware info parsed successfully.");

    if (sys_enable_config.mdm_en) {
        memset(&modem_info, 0, sizeof(modem_info));
        parse_modem_info(&modem_info);
    }
    LOG_INF("Modem info parsed successfully.");

    if (sys_enable_config.imu_en || sys_enable_config.comp_en || sys_enable_config.baro_en) {
        memset(&sensor_config, 0, sizeof(sensor_config));
        parse_sensor_config(&sensor_config);
    }
    LOG_INF("Sensor config parsed successfully.");

    if (sys_enable_config.gnss_en) {
        memset(&gnss_config, 0, sizeof(gnss_config));
        parse_gnss_config(&gnss_config);
    }
    LOG_INF("GNSS config parsed successfully.");

    if (sys_enable_config.mqtt_en) {
        memset(&mqtt_config, 0, sizeof(mqtt_config));
        parse_mqtt_config(&mqtt_config);
        struct_pass.utf8 = pwd;
        struct_pass.size = strlen(pwd);
        struct_user.utf8 = usr;
        struct_user.size = strlen(usr);
    }

    LOG_INF("MQTT config parsed successfully.");

    if (sys_enable_config.ota_en) {
        memset(&ota_config, 0, sizeof(ota_config));
        parse_ota_config(&ota_config);
        if (ota_config.tls_enabled == false) {
            strncpy(ota_config.cert_tag, "-1", sizeof(ota_config.cert_tag) - 1);
        }
        set_filename();
    }
    LOG_INF("OTA config parsed successfully.");

    memset(&customer_info, 0, sizeof(customer_info));
    parse_customer_info(&customer_info);
    LOG_INF("Customer info parsed successfully.");

    memset(&msg_settings, 0, sizeof(msg_settings));
    parse_message_settings(&msg_settings);
    LOG_INF("Message settings parsed successfully.");

    if (sys_enable_config.debug_mode) {
        print_all_configs();
    }
}
```

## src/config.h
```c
#ifndef CONFIG_H
#define CONFIG_H

#include <stdbool.h>
#include <stdint.h>
#include <zephyr/kernel.h>
#include <zephyr/sys/printk.h>
#include <zephyr/logging/log.h>

#include <stdio.h>
#include <stdlib.h>
#include <psa/crypto.h>
#include <psa/crypto_extra.h>
#include <psa/protected_storage.h>
#include <psa/crypto.h>
#include <string.h>
#include <tfm_ns_interface.h>
#define GPS_READ_BUFFER_SIZE 126  
#define GPS_STARTUP_DELAY_MS 2000  
#define GPS_CONFIG_TIMEOUT_MS 500  
#define GPS_MAX_CONFIG_ATTEMPTS 3
#define M10S_ADDR 0x42
#define NAV_PVT_LEN 92

#define MQTT_MAX_STR_LEN 128
#define MQTT_THREAD_STACK_SIZE 2048
#define MQTT_THREAD_PRIORITY 1
#define JSON_BUF_SIZE 200
#define BAD_PUBLISH_LIMIT 5
#define MQTT_RECONNECT_DELAY_SEC 10


#define MAX_INPUT_LEN 256
#define BLOB_HEADER_SIZE 0
#define ENTRY_SIZE 128

#define MAX_ENTRIES         63
#define MAX_IV_LEN          16
#define MAX_AAD_LEN         64
#define MAX_CIPHERTEXT_LEN  256
#define FLASH_PAGE_SIZE  4096 
#define ENTRIES_PER_PAGE (FLASH_PAGE_SIZE / ENTRY_SIZE)
#define CONFIG_PAGE_COUNT 3  
#define TOTAL_ENTRIES     (CONFIG_PAGE_COUNT * ENTRIES_PER_PAGE) 
#define ENCRYPTED_BLOB_ADDR ((const uint8_t *)0xf8000)
#define ENCRYPTED_BLOB_ADDR_2 ((const uint8_t *)0xfc000)
#define ENCRYPTED_BLOB_SIZE 12288 
#define FLASH_CRC_PAGE_OFFSET (CONFIG_PAGE_COUNT * FLASH_PAGE_SIZE)
#define FLASH_PAGE_CRC_SIZE  (ENCRYPTED_BLOB_SIZE - FLASH_CRC_PAGE_OFFSET)
#define CRC_LOCATION_OFFSET (ENCRYPTED_BLOB_SIZE - 4)


#define PROVISIONING_SUCCESS            (0)
#define PROVISIONING_ERROR_CRYPTO_INIT  (-100)
#define PROVISIONING_ERROR_KEY_IMPORT   (-101)
#define PROVISIONING_ERROR_KEY_OPEN     (-102)
#define PROVISIONING_ERROR_ENCRYPT      (-103)
#define PROVISIONING_ERROR_DECRYPT      (-104)
#define PROVISIONING_ERROR_IV_GEN       (-105)
#define PROVISIONING_ERROR_VERIFICATION (-106)
#define PROVISIONING_ERROR_KEY_DESTROY  (-107)
#define PROVISIONING_ERROR_BUFFER_SIZE  (-108)

#define NRF_CRYPTO_EXAMPLE_AES_MAX_TEXT_SIZE (100)
#define NRF_CRYPTO_EXAMPLE_AES_BLOCK_SIZE (16)
#define NRF_CRYPTO_EXAMPLE_AES_IV_SIZE (12)
#define NRF_CRYPTO_EXAMPLE_AES_ADDITIONAL_SIZE (35)
#define NRF_CRYPTO_EXAMPLE_AES_GCM_TAG_LENGTH (16)
#define AES_KEY_SIZE (32) 
#define DECRYPTED_OUTPUT_MAX 256

// MODEM INFO
#define LTE_DATA_INTERVAL  K_SECONDS(60)  
#define LTE_BUF_LEN 32

#define MAX_TRIES        3
#define LOCKOUT_MS       30000     
#define AUTO_LOGOUT_MS   60000      

#define MAX_BLOB (8 * 1024) 
#define PBKDF2_ITERATIONS 64000u

#define FOTA_FILE_NAME_MAX_LEN 300
#define DEFAULT_LEN 64
extern char firmware_filename[FOTA_FILE_NAME_MAX_LEN];
extern char json_payload[JSON_BUF_SIZE];
extern char sensor_payload[JSON_BUF_SIZE];
extern char json_payload_lte[JSON_BUF_SIZE];
extern char topic_gps[DEFAULT_LEN];
extern char topic_sensor[DEFAULT_LEN];
extern char topic_lte[DEFAULT_LEN];
extern char json_bmp390[JSON_BUF_SIZE];
extern char json_iis2mdc[JSON_BUF_SIZE];
extern char json_icm42688[JSON_BUF_SIZE];
extern struct mqtt_utf8 struct_pass;
extern struct mqtt_utf8 struct_user;
extern struct k_work fota_work;


typedef struct {
    bool lte_en;
    bool irid_en;
    bool psm_en;
    bool hw_en;
    bool mdm_en;
    bool gnss_en;
    bool imu_en;
    bool comp_en;
    bool baro_en;
    bool mqtt_en;
    bool ota_en;
    bool debug_mode;
    bool factory_mode;

} system_enable_t;

extern system_enable_t sys_enable_config;
#define SYS_EN_LTE_EN        (1 << 0)
#define SYS_EN_IRID_EN       (1 << 1)
#define SYS_EN_PSM_EN        (1 << 2)
#define SYS_EN_HW_EN         (1 << 3)
#define SYS_EN_MDM_EN        (1 << 4)
#define SYS_EN_GNSS_EN       (1 << 5)
#define SYS_EN_IMU_EN        (1 << 6)
#define SYS_EN_COMP_EN       (1 << 7)
#define SYS_EN_BARO_EN       (1 << 8)
#define SYS_EN_MQTT_EN       (1 << 9)
#define SYS_EN_OTA_EN        (1 << 10)
#define SYS_EN_DEBUG_MODE    (1 << 11)
#define SYS_EN_FACTORY_MODE  (1 << 12)

typedef struct {
    int publish_rate;
    char broker_addr[64];
    int broker_port;
    char client_id[64];
    char username[64];
    char password[64];
    bool tls_enabled;
    int qos;
} mqtt_config_t;


typedef struct {
    int check_interval;
    char server_addr[64];
    int server_port;
    char username[64];
    char password[64];
    bool tls_enabled;
    char cert_tag[64];
} ota_config_t;


typedef struct {
    char sn[32];
    char hw_ver[16];    
    char fw_ver[16];   
    bool power_enabled; 
} hardware_info_t;

typedef struct {
    char make[32];   
    char model[32]; 
    char fw_ver[16];    
    char imei[20];    
    char sim[32];    
    char esim[32];      
    uint16_t lte_bandmask;
} modem_info_t;

typedef struct {
    int  sampling_rate;     
    int  filter_window;     
    bool auto_calibrate;  
} sensor_config_t;

typedef struct {
    int update_rate;
    char version[32];
    uint8_t constellation_mask;
    int accuracy_threshold;
} gnss_config_t;

typedef struct {
    char uas_num[32];
    char description[64];
    char uas_status[64];
    char field2[64];
    char field3[64];
    char field4[64];
} customer_info_t;

typedef struct {
    char msg_format[16];  
    char gps_format[16];   
    char units[16];       
} message_settings_t;

typedef struct {
    uint8_t iv[MAX_IV_LEN];
    uint8_t iv_len;

    uint8_t aad[MAX_AAD_LEN];
    uint16_t aad_len;

    uint8_t ciphertext[MAX_CIPHERTEXT_LEN];
    uint16_t ciphertext_len;

    uint32_t mem_offset;  
} ConfigEntry;


extern ConfigEntry entries[MAX_ENTRIES];
extern int num_entries;

extern mqtt_config_t mqtt_config;
extern ota_config_t ota_config;
extern hardware_info_t hw_info;
extern modem_info_t modem_info;
extern sensor_config_t sensor_config;
extern gnss_config_t gnss_config;
extern customer_info_t customer_info;
extern message_settings_t message_settings;

void parse_encrypted_blob(void);
const char *get_config(const char *aad);
void config_init(void);
uint32_t manual_crc32(const uint8_t *data, size_t len);
int update_crc(void);

enum fota_state {
    FOTA_IDLE,
    FOTA_CONNECTED,
    FOTA_DOWNLOADING,
    FOTA_READY_TO_APPLY,
    FOTA_APPLYING,
};


#endif // CONFIG_H
```

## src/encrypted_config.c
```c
#include <stdint.h>
#include <inttypes.h>

uint8_t config_iv_1[12] = {0xcf, 0x3d, 0x37, 0xe1, 0x3c, 0xf9, 0xc8, 0x24, 0x14, 0xb8, 0x2c, 0xc1};

uint8_t encrypted_config_1[19] = {0x51, 0x4a, 0x46, 0x57, 0x94, 0xc5, 0xb0, 0x3e, 0x1c, 0x80, 0x15, 0xdf, 0x0d, 0x0e, 0x27, 0x28, 0xcd, 0xad, 0xb8};

uint8_t additional_auth_data_1[19] = {0x46, 0x69, 0x65, 0x6c, 0x64, 0x5f, 0x6d, 0x71, 0x74, 0x74, 0x5f, 0x68, 0x6f, 0x73, 0x74, 0x6e, 0x61, 0x6d, 0x65};

uint8_t config_iv_2[12] = {0xf3, 0xe9, 0xf5, 0x5e, 0x18, 0x45, 0x99, 0xb6, 0x3c, 0x24, 0xff, 0x46};

uint8_t encrypted_config_2[29] = {0x8d, 0x9f, 0xca, 0x87, 0x69, 0x22, 0xa4, 0x85, 0x0b, 0xaa, 0x38, 0x2b, 0xea, 0x3a, 0x53, 0xa2, 0x06, 0x32, 0x30, 0x97, 0x9f, 0x2d, 0xf6, 0x5c, 0xf3, 0x75, 0xff, 0xaa, 0x0f};

uint8_t additional_auth_data_2[19] = {0x46, 0x69, 0x65, 0x6c, 0x64, 0x5f, 0x6d, 0x71, 0x74, 0x74, 0x5f, 0x68, 0x6f, 0x73, 0x74, 0x6e, 0x61, 0x6d, 0x65};

uint8_t config_iv_3[12] = {0x3e, 0x8d, 0x50, 0x15, 0x3b, 0x1b, 0x5b, 0xb2, 0x88, 0x34, 0x3f, 0xd2};

uint8_t encrypted_config_3[29] = {0xa1, 0xa7, 0x91, 0x5a, 0x51, 0x25, 0xd5, 0xad, 0x6a, 0x38, 0xd3, 0x76, 0x9f, 0x11, 0xff, 0xb1, 0xf5, 0x10, 0x68, 0xc9, 0x08, 0x31, 0xef, 0x1d, 0x38, 0x24, 0xba, 0xf6, 0x45};

uint8_t additional_auth_data_3[19] = {0x46, 0x69, 0x65, 0x6c, 0x64, 0x5f, 0x6d, 0x71, 0x74, 0x74, 0x5f, 0x68, 0x6f, 0x73, 0x74, 0x6e, 0x61, 0x6d, 0x65};

uint8_t config_iv_4[12] = {0x2d, 0x1d, 0x44, 0x6f, 0xce, 0x63, 0x9b, 0xcc, 0xf0, 0xa1, 0xee, 0xb5};

uint8_t encrypted_config_4[21] = {0x37, 0xa4, 0x91, 0x9a, 0x87, 0x4a, 0x79, 0x9e, 0x87, 0xf9, 0x35, 0xc2, 0xf5, 0x7c, 0x85, 0xa7, 0xba, 0xb5, 0xad, 0x91, 0xe6};

uint8_t additional_auth_data_4[19] = {0x46, 0x69, 0x65, 0x6c, 0x64, 0x5f, 0x6d, 0x71, 0x74, 0x74, 0x5f, 0x68, 0x6f, 0x73, 0x74, 0x6e, 0x61, 0x6d, 0x65};

uint8_t config_iv_5[12] = {0xd3, 0xe8, 0xac, 0xf7, 0xf5, 0xf4, 0xef, 0x05, 0xee, 0x7c, 0x2a, 0xc3};

uint8_t encrypted_config_5[27] = {0xb7, 0xf5, 0x52, 0x9f, 0x1c, 0x62, 0x42, 0xab, 0x35, 0xac, 0xc4, 0x47, 0x27, 0xe6, 0x79, 0x68, 0x72, 0x15, 0xe6, 0x9a, 0x4c, 0x28, 0x95, 0xb1, 0xa7, 0x59, 0xc4};

uint8_t additional_auth_data_5[19] = {0x46, 0x69, 0x65, 0x6c, 0x64, 0x5f, 0x6d, 0x71, 0x74, 0x74, 0x5f, 0x68, 0x6f, 0x73, 0x74, 0x6e, 0x61, 0x6d, 0x65};
```

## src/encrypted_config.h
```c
extern uint8_t config_iv_1[12];

extern uint8_t encrypted_config_1[19];

extern uint8_t additional_auth_data_1[19];

extern uint8_t config_iv_2[12];

extern uint8_t encrypted_config_2[29];

extern uint8_t additional_auth_data_2[19];

extern uint8_t config_iv_3[12];

extern uint8_t encrypted_config_3[29];

extern uint8_t additional_auth_data_3[19];

extern uint8_t config_iv_4[12];

extern uint8_t encrypted_config_4[21];

extern uint8_t additional_auth_data_4[19];

extern uint8_t config_iv_5[12];

extern uint8_t encrypted_config_5[27];

extern uint8_t additional_auth_data_5[19];
```

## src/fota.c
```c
/*
 * Copyright (c) 2019-2023 Nordic Semiconductor ASA
 *
 * SPDX-License-Identifier: LicenseRef-Nordic-5-Clause
 */

#include "fota.h"

#include <nrf_socket.h>
#include "heartbeat.h"


fota_callback_t state_callback = NULL;
struct k_work fota_work;

LOG_MODULE_REGISTER(fota, LOG_LEVEL_INF);

/**
 * @brief Set FOTA state and notify callback
 */
void set_state(enum fota_state new_state, int error)
{
    if (current_state == new_state) {
        return;
    }

    current_state = new_state;
    
    LOG_INF("FOTA state changed to %d (error: %d)", new_state, error);

    if (state_callback) {
        state_callback(new_state, error);
    }
}



/**
 * @brief FOTA download event handler
 */
void fota_dl_handler(const struct fota_download_evt *evt)
{
    switch (evt->id) {
    case FOTA_DOWNLOAD_EVT_ERROR:
        LOG_ERR("FOTA download error");
        set_state(FOTA_CONNECTED, -EIO);
        break;
    case FOTA_DOWNLOAD_EVT_FINISHED:
        LOG_INF("FOTA download finished");
        set_state(FOTA_READY_TO_APPLY, 0);
        fota_apply_update();
        break;
    case FOTA_DOWNLOAD_EVT_PROGRESS:
        LOG_INF("FOTA download progress: %d%%", evt->progress);
        break;
    default:
        break;
    }
}


/**
 * @brief Download firmware from configured host
 */
int download_firmware(void)
{
    int err;
    

    err = fota_download_init(fota_dl_handler);
    if (err) {
        LOG_ERR("fota_download_init() failed, err %d", err);
        return err;
    }

    
    LOG_INF("Starting firmware download from %s%s", ota_config.server_addr, firmware_filename);
    ktd2026_blink_yellow_1hz_30();
    err = fota_download_start(ota_config.server_addr, firmware_filename, atoi(ota_config.cert_tag), 0, 0);
    if (err) {
        LOG_ERR("fota_download_start() failed, err %d", err);
        ktd2026_blink_red_1hz_30();
        return err;
    }

    
    
    return 0;
}

/**
 * @brief FOTA work callback function
 */
void fota_work_cb(struct k_work *work)
{
    int err;

    ARG_UNUSED(work);

    switch (current_state) {
    case FOTA_DOWNLOADING:
        err = download_firmware();
        if (err) {
            set_state(FOTA_CONNECTED, err);
        }
        break;
    case FOTA_APPLYING:
        LOG_INF("Applying firmware update - rebooting...");
        lte_lc_power_off();
        sys_reboot(SYS_REBOOT_WARM);
        break;
    default:
        break;
    }
}

/**
 * @brief Initialize FOTA subsystem
 */
int fota_init(fota_callback_t callback)
{
    state_callback = callback;
    boot_write_img_confirmed();
    k_work_init(&fota_work, fota_work_cb);
    return 0;
}

/**
 * @brief Check FOTA server for updates
 */
int check_fota_server(void)
{
    switch (current_state) {
    case FOTA_IDLE:
        break;
        
    case FOTA_CONNECTED:
        set_state(FOTA_DOWNLOADING, 0);
        LOG_INF("Checking for FOTA updates...");
        k_work_submit(&fota_work);
        break;
        
    case FOTA_DOWNLOADING:
        LOG_INF("FOTA download already in progress");
        return -EBUSY;
        
    case FOTA_READY_TO_APPLY:
        LOG_INF("FOTA update ready - call fota_apply_update()");
        return 0;
        
    case FOTA_APPLYING:
        LOG_INF("FOTA update being applied");
        return -EBUSY;
        
    default:
        LOG_ERR("Invalid FOTA state: %d", current_state);
        set_state(FOTA_IDLE, -EINVAL);
        return -EINVAL;
    }

    return 0;
}

/**
 * @brief Apply FOTA update
 */
int fota_apply_update(void)
{
    if (current_state != FOTA_READY_TO_APPLY) {
        return -EPERM;
    }

    set_state(FOTA_APPLYING, 0);
    k_work_submit(&fota_work);
    return 0;
}

/**
 * @brief Get current FOTA state
 */
enum fota_state fota_get_state(void)
{
    return current_state;
}

/**
 * @brief Cancel FOTA operation
 */
int fota_cancel(void)
{
    switch (current_state) {
    case FOTA_DOWNLOADING:
        fota_download_cancel();
        set_state(FOTA_CONNECTED, 0);
        break;
    case FOTA_READY_TO_APPLY:
        set_state(FOTA_CONNECTED, 0);
        break;
    default:
        return -EPERM;
    }

    return 0;
}
```
